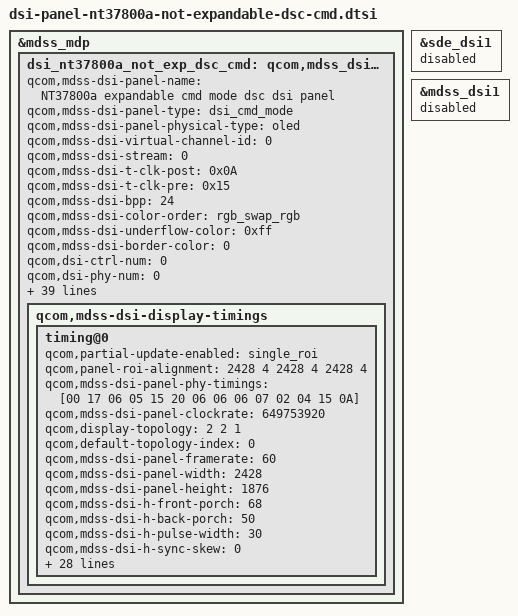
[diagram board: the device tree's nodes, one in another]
/* Copyright (c) 2014, Code Aurora Forum. All rights reserved.
 *
 * This program is free software; you can redistribute it and/or modify
 * it under the terms of the GNU General Public License version 2 and
 * only version 2 as published by the Free Software Foundation.
 *
 * This program is distributed in the hope that it will be useful,
 * but WITHOUT ANY WARRANTY; without even the implied warranty of
 * MERCHANTABILITY or FITNESS FOR A PARTICULAR PURPOSE.  See the
 * GNU General Public License for more details.
 */

&mdss_mdp {
    dsi_nt37800a_not_exp_dsc_cmd: qcom,mdss_dsi_nt37800a_not_exp_dsc_cmd {
    qcom,mdss-dsi-panel-name = "NT37800a expandable cmd mode dsc dsi panel";
		qcom,mdss-dsi-panel-type = "dsi_cmd_mode";
		qcom,mdss-dsi-panel-physical-type = "oled";
		qcom,mdss-dsi-virtual-channel-id = <0>;
		qcom,mdss-dsi-stream = <0>;
		qcom,mdss-dsi-t-clk-post = <0x0A>;
		qcom,mdss-dsi-t-clk-pre = <0x15>;
		qcom,mdss-dsi-bpp = <24>;
		qcom,mdss-dsi-color-order = "rgb_swap_rgb";
		qcom,mdss-dsi-underflow-color = <0xff>;
		qcom,mdss-dsi-border-color = <0>;
		qcom,dsi-ctrl-num = <0>;
		qcom,dsi-phy-num = <0>;
		qcom,dsi-select-clocks = "mux_byte_clk0", "mux_pixel_clk0";
		qcom,mdss-dsi-traffic-mode = "burst_mode";
		qcom,mdss-dsi-lane-map = "lane_map_0123";
		qcom,mdss-dsi-bllp-eof-power-mode;
		qcom,mdss-dsi-bllp-power-mode;
		qcom,mdss-dsi-lane-0-state;
		qcom,mdss-dsi-lane-1-state;
		qcom,mdss-dsi-lane-2-state;
		qcom,mdss-dsi-lane-3-state;
		qcom,mdss-dsi-reset-sequence = <1 10>, <0 2>, <1 10>;
		lge,mdss-dsi-reset-keep-high-after-off-cmd = <180>;
		qcom,mdss-dsi-dma-trigger = "trigger_sw";
		qcom,mdss-dsi-mdp-trigger = "none";
		qcom,mdss-dsi-te-pin-select = <1>;
		qcom,mdss-dsi-wr-mem-start = <0x2c>;
		qcom,mdss-dsi-wr-mem-continue = <0x3c>;
		qcom,mdss-dsi-te-dcs-command = <1>;
		//qcom,mdss-dsi-te-check-enable;
		//qcom,mdss-dsi-te-using-te-pin;
		qcom,mdss-dsi-lp11-init;
		qcom,mdss-dsi-tx-eot-append;
		qcom,ulps-enabled;

		qcom,mdss-dsi-panel-hdr-enabled;
		qcom,mdss-dsi-panel-hdr-color-primaries = <14500 15500 32000
			17000 15500 30000 8000 3000>;
		qcom,mdss-dsi-panel-peak-brightness = <4200000>;
		qcom,mdss-dsi-panel-blackness-level = <3230>;

		qcom,mdss-pan-physical-width-dimension = <156>;
		qcom,mdss-pan-physical-height-dimension = <121>;

		//lge,use-dim-ctrl;
		/* Brightness Map List */
		lge,blmap = <
			0
			5 5 5 5 5 5 5 5 5 5 6 6 7 7 8 8 9 9 10 10
			11 11 12 12 13 13 14 14 15 15 16 16 17 17 18 18 20 21 23 24
			26 28 29 31 32 34 36 37 39 40 42 44 45 47 48 50 52 53 55 56
			58 61 64 67 70 72 75 78 81 84 87 90 93 95 98 101 104 107 110 113
			116 120 125 130 127 132 136 141 146 151 155 160 165 170 174 179 184 189 193 198
			203 208 212 217 222 227 231 236 241 247 252 258 263 269 274 279 285 290 296 301
			307 312 317 323 328 334 339 344 350 355 361 366 372 377 385 392 400 408 415 423
			430 436 444 451 459 466 474 482 489 497 505 512 520 528 535 543 551 558 568 577
			586 596 605 614 623 632 642 651 660 669 679 688 697 706 715 725 734 743 752 761
			771 780 789 801 812 824 836 847 859 870 882 894 905 917 929 940 952 963 975 987
			998 1010 1022 1033 1045 1056 1068 1079 1090 1102 1113 1124 1135 1146 1158 1169 1180 1191 1202 1214
			1225 1236 1247 1258 1270 1281 1292 1303 1314 1326 1337 1348 1364 1379 1395 1410 1426 1441 1457 1472
			1488 1503 1519 1534 1550 1565 1581 1596 1612 1627 1643 1658 1674 1689 1705 1708 1710 1713 1715 1718
			1720 1723 1725 1728 1730 1733 1735 1738 1740 1743 1745 1748 1750 1753 1755 1758 1762 1765 1768 1772
			1775 1778 1782 1785 1788 1792 1795 1798 1802 1805 1808 1812 1815 1818 1822 1825 1828 1832 1835 1838
			1842 1845 1848 1852 1855 1858 1862 1865 1868 1872 1875 1878 1882 1885 1888 1892 1895 1898 1902 1905
			1908 1912 1915 1918 1922 1925 1928 1932 1935 1938 1942 1945 1948 1952 1955 1958 1962 1965 1968 1972
			1975 1978 1982 1985 1988 1992 1995 1998 2002 2005 2008 2011 2013 2016 2019 2022 2025 2027 2030 2033
			2036 2039 2041 2044 2047
		>;

		lge,blmap-ex = <
			0
			16 16 16 16 16 16 16 16 16 25 35 44 53 62 72 81 90 99 109 118
			127 136 146 155 164 173 183 192 201 210 220 229 238 247 257 266 273 281 288 295
			303 310 317 325 332 339 347 354 361 369 376 383 391 398 405 413 420 427 435 442
			449 457 464 471 479 486 493 501 508 515 523 530 537 545 552 572 592 612 632 652
			672 692 712 732 752 772 792 812 832 852 872 892 912 932 952 972 992 1009 1026 1043
			1060 1076 1093 1110 1127 1144 1161 1178 1195 1212 1228 1245 1262 1279 1296 1310 1325 1339 1353 1368
			1382 1396 1411 1425 1439 1453 1468 1482 1496 1511 1525 1539 1554 1568 1568 1568 1568 1568 1568 1568
			1589 1611 1632 1653 1674 1696 1717 1738 1759 1781 1802 1823 1844 1866 1887 1908 1929 1951 1972 1972
			1972 1972 1972 1972 1972 1972 1972 1972 1972 1972 1972 1972 1972 1972 1972 1972 1972 1972 1972 1972
			1972 1972 1972 1972 1972 1972 1972 1972 1972 1972 1972 1972 1972 1972 1972 1972 1972 1972 1972 1972
			1972 1972 1972 1972 1972 1972 1972 1972 1972 1972 1972 1972 1972 1972 1972 1972 1972 1972 1972 1972
			1972 1972 1972 1972 1972 1972 1972 1972 1972 1972 1972 1972 1972 1972 1972 1972 1972 1972 1972 1972
			1972 1972 1972 1972 1972 1972 1972 1972 1972 1972 1972 1972 1972 1972 1972
		>;

		lge,mdss-dsi-nolp-command = [
			05 01 00 00 00 00 01 13
		];
		lge,mdss-dsi-nolp-command-state = "dsi_lp_mode";
		lge,mdss-dsi-lp2-command = [
			05 01 00 00 00 00 01 12
		];
		lge,mdss-dsi-lp2-command-state = "dsi_lp_mode";

		qcom,mdss-dsi-display-timings {
			timing@0{
				qcom,partial-update-enabled = "single_roi";
				qcom,panel-roi-alignment = <2428 4 2428 4 2428 4>;
				qcom,mdss-dsi-panel-phy-timings = [00 17 06 05 15 20 06 06 06 07 02 04 15 0A]; /* To Do */
				qcom,mdss-dsi-panel-clockrate = <649753920>;
				qcom,display-topology = <2 2 1>;
				qcom,default-topology-index = <0>;
				qcom,mdss-dsi-panel-framerate = <60>;
				qcom,mdss-dsi-panel-width = <2428>;
				qcom,mdss-dsi-panel-height = <1876>;
				qcom,mdss-dsi-h-front-porch = <68>;
				qcom,mdss-dsi-h-back-porch = <50>;
				qcom,mdss-dsi-h-pulse-width = <30>;
				qcom,mdss-dsi-h-sync-skew = <0>;
				qcom,mdss-dsi-v-back-porch = <2>;
				qcom,mdss-dsi-v-front-porch = <4>;
				qcom,mdss-dsi-v-pulse-width = <2>;
				qcom,mdss-dsi-h-left-border = <0>;
				qcom,mdss-dsi-h-right-border = <0>;
				qcom,mdss-dsi-v-top-border = <0>;
				qcom,mdss-dsi-v-bottom-border = <0>;
				qcom,mdss-dsi-h-sync-pulse = <0>;
				//qcom,mdss-mdp-transfer-time-us = <15000>;

				qcom,mdss-dsi-on-command = [
					39 01 00 00 00 00 06 F0 55 AA 52 08 00
					39 01 00 00 00 00 03 B5 80 42
					15 01 00 00 00 00 02 6F 02
					15 01 00 00 00 00 02 C1 3F
					15 01 00 00 00 00 02 6F 05
					39 01 00 00 00 00 05 B5 7F 4B 1A 50
					15 01 00 00 00 00 02 6F 0B
					39 01 00 00 00 00 04 B5 4B 1A 50
					15 01 00 00 00 00 02 6F 13
					39 01 00 00 00 00 0D B7 45 56 78 9A BC DE FF FF FF FF FF FF
					15 01 00 00 00 00 02 6F 1F
					39 01 00 00 00 00 19 B7 20 09 F2 DB C4 AD 96 7F 68 51 3A 23 0C FF FF FF FF FF FF FF FF FF FF FF
					39 01 00 00 00 00 08 B7 DC BA 98 76 54 32 10
					39 01 00 00 00 00 10 B2 01 63 20 20 00 08 08 00 00 00 30 00 00 00 00
					15 01 00 00 00 00 02 6F 0F
					39 01 00 00 00 00 0C B2 80 80 80 00 80 00 80 00 00 00 00
					39 01 00 00 00 00 0D B3 00 01 00 64 00 64 00 D2 00 D2 01 36
					15 01 00 00 00 00 02 6F 0C
					39 01 00 00 00 00 0D B3 01 36 01 A4 01 A4 02 26 02 26 02 BC
					15 01 00 00 00 00 02 6F 18
					39 01 00 00 00 00 0D B3 02 BC 03 70 03 70 04 20 04 20 0F FF
					15 01 00 00 00 00 02 6F 24
					39 01 00 00 00 00 09 B3 02 A0 0F 87 0F 87 0F FF
					39 01 00 00 00 00 13 B4 00 6E 06 AE 06 75 06 75 06 3C 06 3C 04 3B 04 3B 02 3A
					15 01 00 00 00 00 02 6F 12
					39 01 00 00 00 00 17 B4 00 6E 00 6E 00 6E 00 6E 00 6E 00 6E 00 6E 00 6E 00 6E 00 6E 00 6E
					15 01 00 00 00 00 02 6F 26
					39 01 00 00 00 00 0B B4 02 FC 02 FC 02 FC 02 FC 02 FC
					39 01 00 00 00 00 05 B9 90 AB 04 04
					39 01 00 00 00 00 09 BA 03 BC 00 10 00 08 00 01
					39 01 00 00 00 00 09 BB 03 BC 00 10 00 08 00 21
					39 01 00 00 00 00 03 BD 03 AA
					39 01 00 00 00 00 06 BE 09 0E 11 10 1F
					39 01 00 00 00 00 03 C0 76 F3
					15 01 00 00 00 00 02 6F 02
					15 01 00 00 00 00 02 C0 00
					39 01 00 00 00 00 08 C1 00 72 00 00 72 00 72
					15 01 00 00 00 00 02 C2 01
					39 01 00 00 00 00 0A C3 00 7F 01 01 00 00 00 00 04
					39 01 00 00 00 00 0A C4 00 00 18 00 00 00 00 00 00
					39 01 00 00 00 00 03 C5 11 31
					39 01 00 00 00 00 08 C6 55 55 55 55 00 05 00
					15 01 00 00 00 00 02 C8 0D
					15 01 00 00 00 00 02 C9 84
					15 01 00 00 00 00 02 CA 33
					15 01 00 00 00 00 02 CB 88
					15 01 00 00 00 00 02 6F 09
					15 01 00 00 00 00 02 B2 40
					39 01 00 00 00 00 06 F0 55 AA 52 08 01
					39 01 00 00 00 00 03 B0 00 00
					39 01 00 00 00 00 03 B3 03 03
					39 01 00 00 00 00 11 B7 14 14 14 14 14 14 14 14 14 14 14 14 14 14 14 14
					39 01 00 00 00 00 03 B1 00 00
					39 01 00 00 00 00 03 B4 03 03
					39 01 00 00 00 00 0F B8 41 41 41 41 41 41 41 41 41 41 41 41 41 41
					39 01 00 00 00 00 0B B5 00 98 00 98 00 98 00 98 00 98
					39 01 00 00 00 00 0B B6 01 20 01 20 01 20 01 20 01 20
					39 01 00 00 00 00 11 B9 1E 1A 1E 1A 1E 1A 1E 1A 1E 1A 1E 1A 1E 1A 1E 1A
					39 01 00 00 00 00 05 BA 10 1F 10 1F
					15 01 00 00 00 00 02 CF 5C
					39 01 00 00 00 00 19 C2 00 98 01 20 00 98 01 20 00 98 01 20 00 98 01 20 00 98 01 20 00 98 01 20
					15 01 00 00 00 00 02 C4 10
					15 01 00 00 00 00 02 C7 01
					15 01 00 00 00 00 02 6F 01
					39 01 00 00 00 00 05 CE 28 01 00 0C
					39 01 00 00 00 00 03 CD 05 82
					39 01 00 00 00 00 06 F0 55 AA 52 08 02
					15 01 00 00 00 00 02 CC 30
					15 01 00 00 00 00 02 BF 00
					39 01 00 00 00 00 19 B0 00 00 01 4C 02 94 02 A0 02 AC 02 B8 02 C0 02 CC 02 D8 02 E0 02 EC 03 00
					39 01 00 00 00 00 19 B1 03 24 03 48 03 7C 03 B0 03 E4 04 3C 04 8C 04 D8 05 1C 05 60 05 98 05 D0
					39 01 00 00 00 00 17 B2 05 EC 06 08 06 24 06 40 06 58 06 70 06 84 06 9C 06 AC 06 B8 06 B8
					39 01 00 00 00 00 19 B3 00 00 01 30 02 5C 02 68 02 74 02 7C 02 88 02 90 02 9C 02 A4 02 AC 02 C0
					39 01 00 00 00 00 19 B4 02 E4 03 04 03 20 03 3C 03 60 03 A4 03 E0 04 1C 04 54 04 8C 04 B8 04 E8
					39 01 00 00 00 00 17 B5 05 00 05 18 05 2C 05 44 05 58 05 6C 05 84 05 98 05 A0 05 A8 05 A8
					39 01 00 00 00 00 19 B6 00 00 02 00 03 FC 04 04 04 0C 04 10 04 18 04 20 04 28 04 30 04 34 04 44
					39 01 00 00 00 00 19 B7 04 60 04 78 04 9C 04 C0 04 E8 05 34 05 78 05 C4 06 08 06 48 06 84 06 C0
					39 01 00 00 00 00 17 B8 06 E0 06 FC 07 1C 07 38 07 50 07 68 07 84 07 9C 07 AC 07 C0 07 C0
					15 01 00 00 00 00 02 BF 01
					39 01 00 00 00 00 19 B0 00 00 01 48 02 8C 02 A0 02 B4 02 C0 02 D0 02 DC 02 EC 03 00 03 14 03 3C
					39 01 00 00 00 00 19 B1 03 88 03 C8 04 08 04 4C 04 88 04 F8 05 60 05 C0 06 10 06 64 06 A8 06 F0
					39 01 00 00 00 00 17 B2 07 10 07 34 07 58 07 78 07 98 07 B8 07 D8 07 F8 08 14 08 2C 08 2C
					39 01 00 00 00 00 19 B3 00 00 01 38 02 6C 02 7C 02 8C 02 98 02 A0 02 AC 02 B8 02 C4 02 D0 02 EC
					39 01 00 00 00 00 19 B4 03 20 03 54 03 84 03 B4 03 E0 04 38 04 88 04 D4 05 18 05 58 05 94 05 CC
					39 01 00 00 00 00 17 B5 05 EC 06 08 06 24 06 44 06 5C 06 74 06 90 06 A8 06 B8 06 C4 06 C4
					39 01 00 00 00 00 19 B6 00 00 01 F8 03 F0 03 FC 04 08 04 10 04 18 04 1C 04 24 04 34 04 40 04 60
					39 01 00 00 00 00 19 B7 04 98 04 D4 05 0C 05 48 05 80 05 E8 06 4C 06 AC 07 04 07 5C 07 A8 07 F4
					39 01 00 00 00 00 17 B8 08 18 08 40 08 64 08 8C 08 B0 08 D0 08 F4 09 18 09 30 09 48 09 48
					15 01 00 00 00 00 02 BF 02
					39 01 00 00 00 00 19 B0 00 00 01 48 02 8C 02 A8 02 C4 02 D8 02 EC 03 04 03 18 03 34 03 50 03 88
					39 01 00 00 00 00 19 B1 03 F4 04 4C 04 9C 04 E8 05 30 05 B8 06 30 06 A0 07 04 07 60 07 B4 08 04
					39 01 00 00 00 00 17 B2 08 30 08 58 08 80 08 A8 08 D0 08 F8 09 20 09 48 09 68 09 88 09 88
					39 01 00 00 00 00 19 B3 00 00 01 3C 02 74 02 8C 02 A0 02 AC 02 BC 02 CC 02 D8 02 EC 02 FC 03 20
					39 01 00 00 00 00 19 B4 03 68 03 B4 03 F0 04 30 04 68 04 D4 05 34 05 8C 05 DC 06 28 06 6C 06 B4
					39 01 00 00 00 00 17 B5 06 D8 06 F8 07 1C 07 40 07 5C 07 78 07 98 07 B4 07 C8 07 DC 07 DC
					39 01 00 00 00 00 19 B6 00 00 01 F8 03 EC 04 00 04 10 04 1C 04 28 04 34 04 40 04 58 04 6C 04 98
					39 01 00 00 00 00 19 B7 04 F0 05 48 05 94 05 E0 06 28 06 AC 07 28 07 9C 08 08 08 70 08 CC 09 28
					39 01 00 00 00 00 17 B8 09 54 09 84 09 B0 09 DC 0A 08 0A 34 0A 60 0A 8C 0A AC 0A C8 0A C8
					15 01 00 00 00 00 02 BF 03
					39 01 00 00 00 00 19 B0 00 00 01 20 02 3C 02 60 02 80 02 9C 02 B8 02 D0 02 EC 03 0C 03 28 03 68
					39 01 00 00 00 00 19 B1 03 E0 04 44 04 94 04 E4 05 2C 05 B4 06 30 06 A0 07 00 07 60 07 B4 08 08
					39 01 00 00 00 00 17 B2 08 30 08 5C 08 84 08 AC 08 D4 09 00 09 28 09 50 09 70 09 90 09 90
					39 01 00 00 00 00 19 B3 00 00 01 14 02 28 02 40 02 58 02 6C 02 80 02 90 02 A4 02 B8 02 CC 02 F8
					39 01 00 00 00 00 19 B4 03 48 03 9C 03 E0 04 24 04 60 04 D0 05 30 05 88 05 D8 06 28 06 70 06 B8
					39 01 00 00 00 00 17 B5 06 DC 06 FC 07 20 07 44 07 64 07 80 07 9C 07 BC 07 D0 07 E4 07 E4
					39 01 00 00 00 00 19 B6 00 00 01 B8 03 6C 03 84 03 98 03 AC 03 C0 03 D4 03 E8 04 04 04 1C 04 50
					39 01 00 00 00 00 19 B7 04 BC 05 20 05 74 05 C4 06 10 06 98 07 1C 07 90 07 FC 08 68 08 C8 09 28
					39 01 00 00 00 00 17 B8 09 58 09 84 09 B4 09 E4 0A 10 0A 3C 0A 6C 0A 98 0A B8 0A D8 0A D8
					15 01 00 00 00 00 02 BF 04
					39 01 00 00 00 00 19 B0 00 00 01 00 02 04 02 2C 02 58 02 78 02 9C 02 C0 02 E0 03 04 03 24 03 64
					39 01 00 00 00 00 19 B1 03 E8 04 54 04 A8 04 F8 05 40 05 D0 06 4C 06 BC 07 20 07 88 07 DC 08 34
					39 01 00 00 00 00 17 B2 08 60 08 88 08 B4 08 E0 09 08 09 34 09 5C 09 84 09 A4 09 C4 09 C4
					39 01 00 00 00 00 19 B3 00 00 00 F8 01 EC 02 08 02 24 02 3C 02 58 02 70 02 88 02 A0 02 B8 02 E4
					39 01 00 00 00 00 19 B4 03 44 03 A0 03 E8 04 30 04 70 04 E4 05 4C 05 A4 05 F8 06 4C 06 94 06 E0
					39 01 00 00 00 00 17 B5 07 04 07 28 07 4C 07 70 07 90 07 B0 07 D0 07 EC 08 00 08 14 08 14
					39 01 00 00 00 00 19 B6 00 00 01 88 03 0C 03 2C 03 48 03 64 03 84 03 A0 03 C0 03 DC 03 FC 04 3C
					39 01 00 00 00 00 19 B7 04 B4 05 24 05 7C 05 D4 06 24 06 B4 07 38 07 B4 08 24 08 94 08 F8 09 5C
					39 01 00 00 00 00 17 B8 09 8C 09 C0 09 F0 0A 24 0A 50 0A 80 0A AC 0A DC 0A FC 0B 20 0B 20
					15 01 00 00 00 00 02 BF 05
					39 01 00 00 00 00 19 B0 00 00 00 E4 01 C8 01 F8 02 2C 02 54 02 80 02 A8 02 D4 02 F4 03 18 03 5C
					39 01 00 00 00 00 19 B1 03 E4 04 50 04 A8 04 FC 05 44 05 D0 06 50 06 BC 07 24 07 8C 07 E4 08 3C
					39 01 00 00 00 00 17 B2 08 68 08 94 08 C4 08 F0 09 18 09 44 09 6C 09 98 09 B4 09 D4 09 D4
					39 01 00 00 00 00 19 B3 00 00 00 D8 01 B0 01 D0 01 EC 02 0C 02 2C 02 48 02 68 02 84 02 9C 02 D0
					39 01 00 00 00 00 19 B4 03 38 03 98 03 E4 04 30 04 70 04 E8 05 50 05 AC 06 00 06 58 06 A4 06 EC
					39 01 00 00 00 00 17 B5 07 14 07 38 07 60 07 84 07 A4 07 C4 07 E4 08 04 08 18 08 28 08 28
					39 01 00 00 00 00 19 B6 00 00 01 58 02 AC 02 D4 02 F8 03 20 03 48 03 70 03 98 03 B8 03 DC 04 20
					39 01 00 00 00 00 19 B7 04 A8 05 1C 05 78 05 D4 06 24 06 B8 07 40 07 BC 08 2C 08 A0 09 08 09 6C
					39 01 00 00 00 00 17 B8 09 A0 09 D4 0A 08 0A 3C 0A 6C 0A 9C 0A CC 0A FC 0B 1C 0B 40 0B 40
					15 01 00 00 00 00 02 BF 06
					39 01 00 00 00 00 19 B0 00 00 00 C8 01 90 01 CC 02 04 02 34 02 64 02 94 02 C8 02 E8 03 0C 03 50
					39 01 00 00 00 00 19 B1 03 DC 04 4C 04 A0 04 F8 05 40 05 CC 06 48 06 B4 07 1C 07 84 07 E0 08 3C
					39 01 00 00 00 00 17 B2 08 6C 08 98 08 C4 08 F4 09 20 09 4C 09 78 09 A4 09 C0 09 D8 09 D8
					39 01 00 00 00 00 19 B3 00 00 00 BC 01 78 01 9C 01 BC 01 E0 02 08 02 2C 02 50 02 6C 02 88 02 C0
					39 01 00 00 00 00 19 B4 03 30 03 90 03 DC 04 28 04 6C 04 E4 05 50 05 AC 06 00 06 58 06 A4 06 F4
					39 01 00 00 00 00 17 B5 07 18 07 40 07 68 07 8C 07 B0 07 D4 07 F4 08 18 08 28 08 38 08 38
					39 01 00 00 00 00 19 B6 00 00 01 30 02 5C 02 88 02 B4 02 E8 03 18 03 48 03 78 03 A0 03 C4 04 0C
					39 01 00 00 00 00 19 B7 04 9C 05 10 05 70 05 CC 06 20 06 B4 07 3C 07 B8 08 2C 08 A0 09 0C 09 74
					39 01 00 00 00 00 17 B8 09 AC 09 E0 0A 18 0A 4C 0A 80 0A B0 0A E4 0B 14 0B 34 0B 54 0B 54
					15 01 00 00 00 00 02 BF 07
					39 01 00 00 00 00 19 B0 00 00 00 B4 01 6C 01 AC 01 E8 02 20 02 54 02 8C 02 C0 02 E4 03 08 03 4C
					39 01 00 00 00 00 19 B1 03 D8 04 48 04 A0 04 F8 05 40 05 CC 06 48 06 B8 07 20 07 8C 07 EC 08 4C
					39 01 00 00 00 00 17 B2 08 7C 08 AC 08 D8 09 08 09 3C 09 6C 09 9C 09 CC 09 E0 09 F8 09 F8
					39 01 00 00 00 00 19 B3 00 00 00 A8 01 50 01 78 01 A0 01 CC 01 F4 02 1C 02 44 02 60 02 80 02 BC
					39 01 00 00 00 00 19 B4 03 30 03 94 03 E0 04 2C 04 70 04 E8 05 50 05 B0 06 0C 06 64 06 B4 07 04
					39 01 00 00 00 00 17 B5 07 2C 07 54 07 7C 07 A4 07 CC 07 F0 08 18 08 3C 08 4C 08 5C 08 5C
					39 01 00 00 00 00 19 B6 00 00 01 14 02 24 02 5C 02 90 02 C8 03 00 03 38 03 6C 03 94 03 B8 04 04
					39 01 00 00 00 00 19 B7 04 9C 05 10 05 70 05 CC 06 20 06 B8 07 40 07 C0 08 38 08 AC 09 20 09 8C
					39 01 00 00 00 00 17 B8 09 C4 09 FC 0A 34 0A 6C 0A A4 0A DC 0B 14 0B 4C 0B 68 0B 84 0B 84
					15 01 00 00 00 00 02 BF 08
					39 01 00 00 00 00 19 B0 00 00 00 AC 01 58 01 A0 01 E4 02 1C 02 54 02 8C 02 C0 02 E8 03 0C 03 54
					39 01 00 00 00 00 19 B1 03 E8 04 54 04 B0 05 08 05 54 05 E0 06 60 06 D4 07 44 07 B0 08 18 08 7C
					39 01 00 00 00 00 17 B2 08 B0 08 E4 09 14 09 48 09 80 09 BC 09 F4 0A 2C 0A 40 0A 50 0A 50
					39 01 00 00 00 00 19 B3 00 00 00 A4 01 48 01 74 01 A4 01 CC 01 F8 02 24 02 50 02 6C 02 8C 02 C8
					39 01 00 00 00 00 19 B4 03 44 03 A4 03 F0 04 3C 04 80 04 FC 05 68 05 CC 06 28 06 84 06 DC 07 30
					39 01 00 00 00 00 17 B5 07 5C 07 88 07 B4 07 E0 08 0C 08 34 08 60 08 8C 08 9C 08 A8 08 A8
					39 01 00 00 00 00 19 B6 00 00 01 0C 02 18 02 54 02 94 02 CC 03 08 03 40 03 78 03 A0 03 C4 04 10
					39 01 00 00 00 00 19 B7 04 A8 05 1C 05 80 05 E0 06 38 06 D4 07 60 07 E4 08 64 08 E0 09 58 09 CC
					39 01 00 00 00 00 17 B8 0A 08 0A 44 0A 80 0A BC 0A FC 0B 40 0B 80 0B C4 0B D8 0B EC 0B EC
					15 01 00 00 00 00 02 BF 09
					39 01 00 00 00 00 19 B0 00 00 00 8C 01 14 01 7C 01 E4 02 24 02 64 02 A4 02 E4 03 08 03 30 03 7C
					39 01 00 00 00 00 19 B1 04 14 04 84 04 E8 05 48 05 98 06 28 06 B0 07 2C 07 A4 08 20 08 94 09 08
					39 01 00 00 00 00 17 B2 09 40 09 7C 09 B4 09 EC 0A 2C 0A 68 0A A8 0A E4 0A EC 0A F8 0A F8
					39 01 00 00 00 00 19 B3 00 00 00 40 00 84 00 F4 01 60 01 9C 01 D4 02 10 02 48 02 68 02 8C 02 D0
					39 01 00 00 00 00 19 B4 03 58 03 BC 04 0C 04 60 04 A8 05 28 05 A0 06 0C 06 70 06 D4 07 34 07 94
					39 01 00 00 00 00 17 B5 07 C4 07 F4 08 24 08 54 08 84 08 B8 08 E8 09 1C 09 24 09 30 09 30
					39 01 00 00 00 00 19 B6 00 00 00 E0 01 BC 02 14 02 6C 02 AC 02 EC 03 28 03 68 03 90 03 B8 04 08
					39 01 00 00 00 00 19 B7 04 A8 05 20 05 88 05 F0 06 48 06 F4 07 8C 08 18 08 A4 09 2C 09 B0 0A 38
					39 01 00 00 00 00 17 B8 0A 78 0A BC 0B 00 0B 44 0B 94 0B E4 0C 34 0C 84 0C 90 0C 98 0C 98
					15 01 00 00 00 00 02 CE 01
					15 01 00 00 00 00 02 CC 00
					15 01 00 00 00 00 02 BC 11
					39 01 00 00 00 00 11 BD 96 00 69 00 00 96 00 69 BB 44 44 BB EE 11 11 EE
					15 01 00 00 00 00 02 C1 02
					39 01 00 00 00 00 09 C2 19 00 91 00 19 00 91 00
					39 01 00 00 00 00 03 C0 00 00
					39 01 00 00 00 00 06 F0 55 AA 52 08 03
					39 01 00 00 00 00 09 B0 00 00 00 00 00 00 00 02
					15 01 00 00 00 00 02 6F 20
					39 01 00 00 00 00 09 B0 00 00 00 00 00 00 00 00
					15 01 00 00 00 00 02 6F 28
					39 01 00 00 00 00 09 B0 00 00 00 00 00 00 00 00
					39 01 00 00 00 00 03 B1 00 02
					39 01 00 00 00 00 06 B2 00 00 00 06 01
					15 01 00 00 00 00 02 6F 08
					39 01 00 00 00 00 06 B2 00 00 00 06 01
					39 01 00 00 00 00 0A B4 01 01 01 01 01 01 01 01 01
					39 01 00 00 00 00 07 B5 01 00 31 8F 05 0E
					15 01 00 00 00 00 02 6F 0C
					39 01 00 00 00 00 07 B5 01 00 31 8F 05 0E
					39 01 00 00 00 00 12 B6 03 00 00 00 00 00 00 00 00 00 07 00 07 00 07 00 07
					39 01 00 00 00 00 05 BB 11 00 4C DF
					39 01 00 00 00 00 05 BC 11 00 1B D4
					39 01 00 00 00 00 04 C3 00 00 0A
					39 01 00 00 00 00 06 F0 55 AA 52 08 05
					39 01 00 00 00 00 04 B0 03 61 00
					39 01 00 00 00 00 04 B2 04 00 50
					39 01 00 00 00 00 03 B3 86 80
					39 01 00 00 00 00 03 B5 04 05
					39 01 00 00 00 00 05 B7 04 00 00 05
					39 01 00 00 00 00 05 B8 04 00 00 05
					39 01 00 00 00 00 03 C7 03 01
					15 01 00 00 00 00 02 C9 33
					15 01 00 00 00 00 02 CA 33
					39 01 00 00 00 00 04 CB 33 33 33
					15 01 00 00 00 00 02 D8 22
					15 01 00 00 00 00 02 D9 01
					39 01 00 00 00 00 04 D0 00 10 10
					39 01 00 00 00 00 04 D1 00 0F 10
					39 01 00 00 00 00 05 E0 02 00 00 00
					39 01 00 00 00 00 05 E1 02 00 00 01
					39 01 00 00 00 00 05 EC 01 11 00 00
					39 01 00 00 00 00 06 F0 55 AA 52 08 06
					39 01 00 00 00 00 06 B0 2E 2E 2C 2C 0F
					39 01 00 00 00 00 06 B1 0F 0E 0E 00 00
					39 01 00 00 00 00 06 B2 04 04 12 12 13
					39 01 00 00 00 00 06 B3 13 32 32 32 32
					39 01 00 00 00 00 06 B6 2E 2E 2C 2C 0F
					39 01 00 00 00 00 06 B7 0F 0E 0E 00 00
					39 01 00 00 00 00 06 B8 04 04 12 12 13
					39 01 00 00 00 00 06 B9 13 32 32 32 32
					15 01 00 00 00 00 02 D0 01
					39 01 00 00 00 00 06 F0 55 AA 52 08 07
					39 01 00 00 00 00 06 B0 84 40 78 70 00
					39 01 00 00 00 00 06 B1 0c 1c 00 1c 0c
					15 01 00 00 00 00 02 C0 00
					39 01 00 00 00 00 06 F0 55 AA 52 00 00
					39 01 00 00 00 00 05 FF AA 55 A5 80
					15 01 00 00 00 00 02 6F 50
					15 01 00 00 00 00 02 FB 00
					39 01 00 00 00 00 05 FF AA 55 A5 81
					39 01 00 00 00 00 05 FF AA 55 A5 00
					15 01 00 00 00 00 02 35 00
					39 01 00 00 00 00 05 3B 00 10 00 10
					39 01 00 00 00 00 05 51 00 00 0F FF
					15 01 00 00 00 00 02 53 20
					15 01 00 00 00 00 02 03 01
					39 01 00 00 00 00 05 2A 00 00 09 7B
					39 01 00 00 00 00 05 2B 00 00 07 53
					15 01 00 00 00 00 02 90 81
					39 01 00 00 00 00 13 91 89 28 00 04 02 00 01 00 01 B9 00 10 00 00 0B 25 10 D0
					15 01 00 00 00 00 02 2C 00
					05 01 00 00 78 00 01 11
					05 01 00 00 00 00 01 29
					];

				qcom,mdss-dsi-post-panel-on-command = [
					//05 01 00 00 78 00 01 12
					//39 01 00 00 00 00 03 51 07 FF
				];

				qcom,mdss-dsi-off-command = [
					05 01 00 00 00 00 01 28
					05 01 00 00 20 00 01 10
				];

				qcom,compression-mode = "dsc";
				qcom,mdss-dsc-version = <0x11>;
				qcom,mdss-dsc-scr-version = <0x1>;
				qcom,mdss-dsc-slice-height = <4>;
				qcom,mdss-dsc-slice-width = <1214>;
				qcom,mdss-dsc-slice-per-pkt = <2>;
				qcom,mdss-dsc-bit-per-component = <8>;
				qcom,mdss-dsc-bit-per-pixel = <8>;
				qcom,lm-split = <1214 1214>;
				qcom,mdss-dsc-encoders = <2>;
				qcom,mdss-dsc-block-prediction-enable;

				qcom,mdss-dsi-on-command-state = "dsi_lp_mode";
				qcom,mdss-dsi-off-command-state = "dsi_lp_mode";

				qcom,mode-control-dsi-state = "dsi_lp_mode";
				qcom,mdss-dsi-pps-command-state = "dsi_hs_mode";
			};
		};
	};
};

&sde_dsi1 {
	status = "disabled";
};

&mdss_dsi1 {
	status = "disabled";
};
